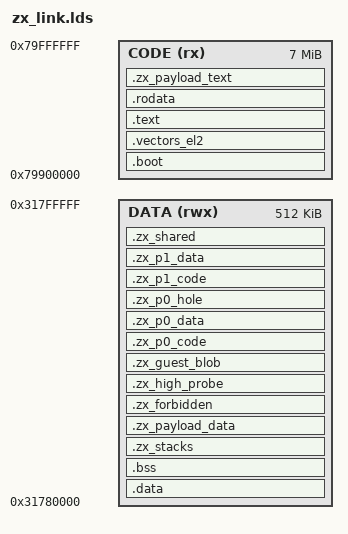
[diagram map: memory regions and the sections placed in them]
/***************************************************************************
 * Copyright (c) 2026 Eclipse ThreadX contributors
 *
 * This program and the accompanying materials are made available under the
 * terms of the MIT License which is available at
 * https://opensource.org/licenses/MIT.
 *
 * AI Disclosure: This file was largely AI-generated by Claude Code (Opus 5).
 * The AI-generated portions may be considered public domain (CC0-1.0)
 * and not subject to the project's licence. The human contributor has
 * reviewed and verified that the code is correct.
 *
 * SPDX-License-Identifier: MIT and CC0-1.0
 **************************************************************************/

/* Link map for the ZoneX stage-2 probe on the NXP S32Z280-594EVB, RTU0 core 0.
 *
 * Code goes to the RTU code SRAM at its instruction-fetch address,
 * 0x79900000, which is also where the core resets: MC_ME_PRTN0_CORE0_ADDR
 * reads 0x79900000 on this board, so a debugger-loaded image needs no
 * relocation to be reached by the reset vector.  That window is writable over
 * the debug AXI port even though NXP's memory map declares it read-only, so a
 * plain "load" works and no LMA alias is required.  A flash-booted image would
 * have to be written through the data alias at 0x32100000.
 *
 * Data, bss, the Hyp stack and the payload's areas go to the RTU-local data
 * SRAM at 0x31780000.  RTU-local traffic does not leave the RTU.
 *
 * The TCMs are deliberately unused.  They are not accessible at reset until
 * their region registers are programmed, and ECC is enabled on this part, so a
 * TCM location must be WRITTEN before it can be read (Cortex-R52 TRM 6.2.2).
 * Nothing needed for early boot can live there, and adding a preload to this
 * image would add a failure mode to one whose whole purpose is to isolate one.
 *
 * A NOTE ON ALIGN, because the two spellings are not equivalent
 *
 * Every ALIGN below is written AFTER the colon, which is the section's
 * ALIGNMENT.  Written before the colon it is the section's ADDRESS, evaluated
 * from a location counter that starts at zero, and it silently overrides
 * "> CODE" -- every section then lands near address 0 and the link fails with
 * "not within region".  The FVP script gets away with the address form only
 * because its region starts at 0x00000000, so both scripts use the safe form.
 *
 * WHAT MAKES THIS SCRIPT DIFFERENT FROM AN ORDINARY BARE-METAL ONE
 *
 * Four areas are not merely aligned but SIZED to whole 64-byte granules,
 * because each is a stage-2 MPU region and PMSAv8-R has a 64-byte granule
 * with an inclusive limit:
 *
 *   .zx_payload_text   region 0, the payload's code
 *   .zx_payload_data   region 1, the payload's data
 *   .zx_forbidden      NO REGION AT ALL -- the whole point
 *   .zx_high_probe     region 16, the high-region experiment
 *
 * .zx_forbidden is placed IMMEDIATELY AFTER .zx_payload_data, adjacent by
 * construction.  An ungranted address far from every grant proves only that
 * unmapped memory faults; the defect class worth catching is a region whose
 * limit or base is out by one granule, and only an adjacent hole catches it.
 * Do not move it, and do not let anything land between the two.
 *
 * TWO MORE REGIONS EXIST ON THIS TARGET AND ARE NOT IN THIS SCRIPT: the
 * hypervisor's console and the GIC, which are MMIO and have fixed addresses.
 * See examples/s32z280_evb/zx_board.c and docs/decisions.md D2.
 *
 * ZoneX's OWN code, data, bss and stack are covered by no region at all --
 * decision D2, not an oversight.  With HSCTLR.BR=1 EL2's own accesses fall
 * back to the background map, while EL0/EL1 accesses that hit no region fault
 * regardless of BR, so the hypervisor costs no region and is protected from
 * the payload precisely by not being mapped.
 */

ENTRY(_start)

__zx_hyp_stack_size = 0x1000;

/* One partition window each.  The code window has to hold the guest blob
   with room to grow; the data window holds the hypervisor-to-guest mailbox
   and nothing else, so one granule would do and four give it slack.  Both
   are whole granules because both are MPU regions.  */
__zx_window_code_size = 0x400;
__zx_window_data_size = 0x100;

MEMORY
{
    CODE (rx)  : ORIGIN = 0x79900000, LENGTH = 0x00700000    /* 7 MB    */
    DATA (rwx) : ORIGIN = 0x31780000, LENGTH = 0x00080000    /* 512 KB  */
}

SECTIONS
{
    /* .boot MUST come first: MC_ME_PRTN0_CORE0_ADDR is 0x79900000 on this
       board, so whatever lands at the start of CODE is what the core executes
       out of reset, and that has to be _start.  It must also be a T32
       instruction, since the core resets in Thumb state -- which is what
       ZX_RESET_IN_THUMB arranges in zx_el2_entry.S.  The vector table needs
       alignment but not a fixed address, because HVBAR is programmed at run
       time, so it follows rather than leads.  */

    .boot :
    {
        KEEP(*(.text.boot))
    } > CODE

    .vectors_el2 :
    {
        KEEP(*(.vectors_el2))
    } > CODE

    .text :
    {
        *(.text*)
        *(.glue_7)
        *(.glue_7t)
    } > CODE

    .rodata :
    {
        *(.rodata*)
        . = ALIGN(4);
    } > CODE

    /* The payload's CODE goes in CODE, on a granule boundary, and is the
       only part of the image in this memory that a stage-2 region covers. */

    .zx_payload_text : ALIGN(64)
    {
        __zx_payload_code_start = .;
        KEEP(*(.zx_payload_text))
        . = ALIGN(64);
        __zx_payload_code_end = .;
    } > CODE

    .data : ALIGN(8)
    {
        __zx_data_start = .;
        *(.data*)
        . = ALIGN(8);
        __zx_data_end = .;
    } > DATA

    .bss (NOLOAD) : ALIGN(8)
    {
        __zx_bss_start = .;
        *(.bss*)
        *(COMMON)
        . = ALIGN(8);
        __zx_bss_end = .;
    } > DATA

    /* The hypervisor's Hyp-mode stack.  SP must stay 8-byte aligned
       (AAPCS), so the area is aligned before its top symbol is taken.  */

    .zx_stacks (NOLOAD) : ALIGN(8)
    {
        . = . + __zx_hyp_stack_size;
        __zx_hyp_stack_top = .;
    } > DATA

    /* ------------------------------------------------------------------
       The partition data areas.  The ORDER of these three is load-bearing.
       ------------------------------------------------------------------ */

    .zx_payload_data : ALIGN(64)
    {
        __zx_payload_data_start = .;
        KEEP(*(.zx_payload_data))
        . = ALIGN(64);
        __zx_payload_data_end = .;
    } > DATA

    /* One granule, covered by NO region.  Adjacent to the payload's data by
       construction -- see the header.  */

    .zx_forbidden (NOLOAD) : ALIGN(64)
    {
        __zx_forbidden_start = .;
        . = . + 64;
        __zx_forbidden_end = .;
    } > DATA

    .zx_high_probe : ALIGN(64)
    {
        __zx_high_probe_start = .;
        KEEP(*(.zx_high_probe))
        . = ALIGN(64);
        __zx_high_probe_end = .;
    } > DATA


    /* ------------------------------------------------------------------
       THE TWO PARTITION WINDOWS.

       .zx_guest_blob is the copy SOURCE: it lives in the hypervisor's own
       memory, covered by no region, and is copied into each partition's
       code window at boot.  That is the path a real guest image takes, and
       it is why a partition's code window is NOLOAD -- there is nothing in
       the ELF to load there, the contents arrive at run time.

       The ORDER of what follows is load-bearing in one place: the ungranted
       granule sits IMMEDIATELY AFTER partition 0's data window, adjacent by
       construction.  An ungranted address far from every grant proves only
       that unmapped memory faults; the defect worth catching is a region
       whose limit is out by one granule, and only an adjacent hole catches
       it.  The ASSERT below is what keeps a later edit from separating
       them.
       ------------------------------------------------------------------ */

    .zx_guest_blob : ALIGN(64)
    {
        __zx_guest_blob_start = .;
        KEEP(*(.zx_guest_blob))
        . = ALIGN(64);
        __zx_guest_blob_end = .;
    } > DATA

    .zx_p0_code (NOLOAD) : ALIGN(64)
    {
        __zx_p0_code_start = .;
        . = . + __zx_window_code_size;
        __zx_p0_code_end = .;
    } > DATA

    .zx_p0_data (NOLOAD) : ALIGN(64)
    {
        __zx_p0_data_start = .;
        . = . + __zx_window_data_size;
        __zx_p0_data_end = .;
    } > DATA

    /* One granule, granted to nobody.  Adjacent to partition 0's data.  */

    .zx_p0_hole (NOLOAD) : ALIGN(64)
    {
        __zx_p0_hole_start = .;
        . = . + 64;
        __zx_p0_hole_end = .;
    } > DATA

    .zx_p1_code (NOLOAD) : ALIGN(64)
    {
        __zx_p1_code_start = .;
        . = . + __zx_window_code_size;
        __zx_p1_code_end = .;
    } > DATA

    .zx_p1_data (NOLOAD) : ALIGN(64)
    {
        __zx_p1_data_start = .;
        . = . + __zx_window_data_size;
        __zx_p1_data_end = .;
    } > DATA

    /* The one granule both partitions can see: written by the publisher,
       read-only to everyone else.  Its own section so that the two regions
       covering it -- one per partition -- describe exactly the same range,
       which is what the validator's shared-range rule requires.  */

    .zx_shared (NOLOAD) : ALIGN(64)
    {
        __zx_shared_start = .;
        . = . + 64;
        __zx_shared_end = .;
    } > DATA
    . = ALIGN(8);
    PROVIDE(end = .);
    PROVIDE(_end = .);

    /* Assert the geometry the region programming depends on, so that a layout
       mistake fails the LINK rather than the run.  An under-aligned base does
       not fault: its low bits land on SH, AP and XN and silently change the
       region's attributes, which is the hardest failure in this architecture
       to see.  */

    ASSERT((__zx_payload_code_start & 63) == 0,
           "payload code region base is not 64-byte aligned")
    ASSERT((__zx_payload_code_end & 63) == 0,
           "payload code region is not a whole number of granules")
    ASSERT((__zx_payload_data_start & 63) == 0,
           "payload data region base is not 64-byte aligned")
    ASSERT((__zx_payload_data_end & 63) == 0,
           "payload data region is not a whole number of granules")
    ASSERT(__zx_forbidden_start == __zx_payload_data_end,
           "the ungranted granule is NOT adjacent to the payload's data region")
    ASSERT((__zx_high_probe_start & 63) == 0,
           "the high-probe region base is not 64-byte aligned")
    ASSERT(__zx_high_probe_start >= __zx_forbidden_end,
           "the high-probe region overlaps the ungranted granule")

    /* The two-partition geometry.  Each of these would otherwise be a
       run-time mystery: an under-aligned window base does not fault, it
       lands on SH, AP and XN and silently changes the region's
       attributes.  */

    ASSERT((__zx_guest_blob_start & 63) == 0,
           "the guest blob is not 64-byte aligned")
    ASSERT((__zx_p0_code_start & 63) == 0,
           "partition 0's code window base is not 64-byte aligned")
    ASSERT((__zx_p0_data_start & 63) == 0,
           "partition 0's data window base is not 64-byte aligned")
    ASSERT((__zx_p1_code_start & 63) == 0,
           "partition 1's code window base is not 64-byte aligned")
    ASSERT((__zx_p1_data_start & 63) == 0,
           "partition 1's data window base is not 64-byte aligned")
    ASSERT((__zx_shared_start & 63) == 0,
           "the shared granule is not 64-byte aligned")
    ASSERT((__zx_shared_end - __zx_shared_start) == 64,
           "the shared area is not exactly one granule")

    ASSERT(__zx_p0_hole_start == __zx_p0_data_end,
           "the ungranted granule is NOT adjacent to partition 0's data window")
    ASSERT(__zx_p1_code_start == __zx_p0_hole_end,
           "something was placed between the ungranted granule and partition 1")

    ASSERT((__zx_guest_blob_end - __zx_guest_blob_start) <= __zx_window_code_size,
           "the guest blob does not fit a partition's code window")
    ASSERT(__zx_window_data_size >= 64,
           "a partition data window must be at least one granule")
}
